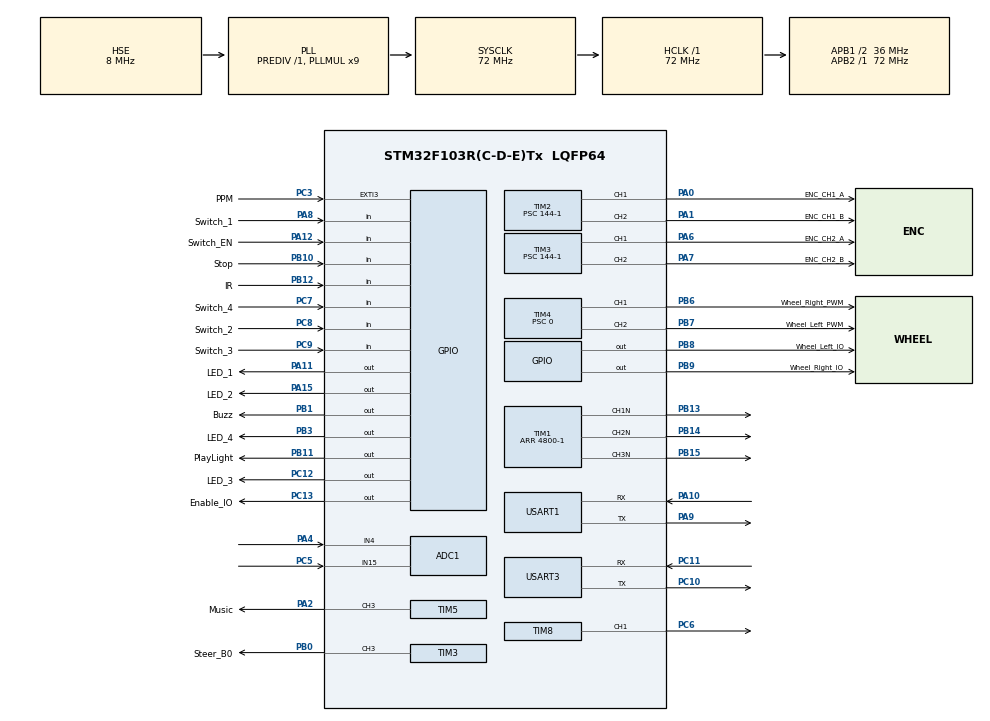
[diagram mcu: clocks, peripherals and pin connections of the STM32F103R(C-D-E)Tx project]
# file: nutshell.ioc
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ADC1.Channel-0\#ChannelRegularConversion=ADC_CHANNEL_4
ADC1.Channel-1\#ChannelRegularConversion=ADC_CHANNEL_15
ADC1.ContinuousConvMode=ENABLE
ADC1.NbrOfConversion=2
ADC1.NbrOfConversionFlag=1
ADC1.Rank-0\#ChannelRegularConversion=1
ADC1.Rank-1\#ChannelRegularConversion=2
ADC1.SamplingTime-0\#ChannelRegularConversion=ADC_SAMPLETIME_239CYCLES_5
ADC1.SamplingTime-1\#ChannelRegularConversion=ADC_SAMPLETIME_239CYCLES_5
ADC1.master=1
Dma.ADC1.0.Direction=DMA_PERIPH_TO_MEMORY
Dma.ADC1.0.Instance=DMA1_Channel1
Dma.ADC1.0.MemDataAlignment=DMA_MDATAALIGN_HALFWORD
Dma.ADC1.0.MemInc=DMA_MINC_ENABLE
Dma.ADC1.0.Mode=DMA_CIRCULAR
Dma.ADC1.0.PeriphDataAlignment=DMA_PDATAALIGN_HALFWORD
Dma.ADC1.0.PeriphInc=DMA_PINC_DISABLE
Dma.ADC1.0.Priority=DMA_PRIORITY_LOW
Dma.Request0=ADC1
Dma.Request1=USART1_TX
Dma.USART1_TX.1.Direction=DMA_MEMORY_TO_PERIPH
Dma.USART1_TX.1.Instance=DMA1_Channel4
Dma.USART1_TX.1.MemDataAlignment=DMA_MDATAALIGN_BYTE
Dma.USART1_TX.1.MemInc=DMA_MINC_ENABLE
Dma.USART1_TX.1.Mode=DMA_NORMAL
Dma.USART1_TX.1.PeriphDataAlignment=DMA_PDATAALIGN_BYTE
Dma.USART1_TX.1.PeriphInc=DMA_PINC_DISABLE
Dma.USART1_TX.1.Priority=DMA_PRIORITY_HIGH
Mcu.Family=STM32F1
Mcu.Name=STM32F103R(C-D-E)Tx
Mcu.Package=LQFP64
Mcu.UserConstants=huart_DBG,$$_USART1_IP_HANDLE_$$;huart_USER,$$_USART3_IP_HANDLE_$$;htim_RC,$$_TIM6_IP_HANDLE_$$
NVIC.DMA1_Channel1_IRQn=true\:0\:0\:false\:false\:true\:false\:true\:true
NVIC.DMA1_Channel4_IRQn=true\:0\:0\:false\:false\:true\:false\:true\:true
NVIC.EXTI3_IRQn=true\:0\:0\:false\:false\:true\:true\:true\:true
NVIC.PriorityGroup=NVIC_PRIORITYGROUP_4
NVIC.TIM6_IRQn=true\:0\:0\:false\:false\:true\:true\:true\:true
NVIC.TIM7_IRQn=true\:15\:0\:false\:false\:true\:false\:true\:true
NVIC.TimeBase=TIM7_IRQn
NVIC.TimeBaseIP=TIM7
PA0-WKUP.GPIO_Label=ENC_CH1_A
PA0-WKUP.GPIO_Speed=GPIO_SPEED_FREQ_HIGH
PA0-WKUP.Signal=S_TIM2_CH1_ETR
PA1.GPIO_Label=ENC_CH1_B
PA1.GPIO_Speed=GPIO_SPEED_FREQ_HIGH
PA1.Signal=S_TIM2_CH2
PA10.Mode=Asynchronous
PA10.Signal=USART1_RX
PA11.GPIO_Label=LED_1
PA11.Signal=GPIO_Output
PA12.GPIO_Label=Switch_EN
PA12.Signal=GPIO_Input
PA13.Mode=Serial_Wire
PA13.Signal=SYS_JTMS-SWDIO
PA14.Mode=Serial_Wire
PA14.Signal=SYS_JTCK-SWCLK
PA15.GPIO_Label=LED_2
PA15.GPIO_Speed=GPIO_SPEED_FREQ_HIGH
PA15.Signal=GPIO_Output
PA2.GPIO_Label=Music
PA2.GPIO_Speed=GPIO_SPEED_FREQ_HIGH
PA2.Signal=S_TIM5_CH3
PA4.Signal=ADCx_IN4
PA6.GPIO_Label=ENC_CH2_A
PA6.GPIO_Speed=GPIO_SPEED_FREQ_HIGH
PA6.Signal=S_TIM3_CH1
PA7.GPIO_Label=ENC_CH2_B
PA7.GPIO_Speed=GPIO_SPEED_FREQ_HIGH
PA7.Signal=S_TIM3_CH2
PA8.GPIO_Label=Switch_1
PA8.GPIO_PuPd=GPIO_PULLUP
PA8.Signal=GPIO_Input
PA9.Mode=Asynchronous
PA9.Signal=USART1_TX
PB0.GPIO_Label=Steer_B0
PB0.GPIO_Speed=GPIO_SPEED_FREQ_HIGH
PB0.Signal=S_TIM3_CH3
PB1.GPIO_Label=Buzz
PB1.Signal=GPIO_Output
PB10.GPIO_Label=Stop
PB10.Signal=GPIO_Input
PB11.GPIO_Label=PlayLight
PB11.Signal=GPIO_Output
PB12.GPIO_Label=IR
PB12.Signal=GPIO_Input
PB13.GPIO_Speed=GPIO_SPEED_FREQ_HIGH
PB13.Mode=Output Compare1 CH1N
PB13.Signal=TIM1_CH1N
PB14.GPIO_Speed=GPIO_SPEED_FREQ_HIGH
PB14.Mode=Output Compare2 CH2N
PB14.Signal=TIM1_CH2N
PB15.GPIO_Speed=GPIO_SPEED_FREQ_HIGH
PB15.Mode=Output Compare3 CH3N
PB15.Signal=TIM1_CH3N
PB3.GPIO_Label=LED_4
PB3.GPIO_Speed=GPIO_SPEED_FREQ_HIGH
PB3.Signal=GPIO_Output
PB6.GPIO_Label=Wheel_Right_PWM
PB6.GPIO_Speed=GPIO_SPEED_FREQ_HIGH
PB6.Signal=S_TIM4_CH1
PB7.GPIO_Label=Wheel_Left_PWM
PB7.Signal=S_TIM4_CH2
PB8.GPIO_Label=Wheel_Left_IO
PB8.GPIO_Speed=GPIO_SPEED_FREQ_HIGH
PB8.Signal=GPIO_Output
PB9.GPIO_Label=Wheel_Right_IO
PB9.GPIO_Speed=GPIO_SPEED_FREQ_HIGH
PB9.Signal=GPIO_Output
PC10.Mode=Asynchronous
PC10.Signal=USART3_TX
PC11.Mode=Asynchronous
PC11.Signal=USART3_RX
PC12.GPIO_Label=LED_3
PC12.GPIO_Speed=GPIO_SPEED_FREQ_HIGH
PC12.Signal=GPIO_Output
PC13-TAMPER-RTC.GPIO_Label=Enable_IO
PC13-TAMPER-RTC.GPIO_Speed=GPIO_SPEED_FREQ_HIGH
PC13-TAMPER-RTC.Signal=GPIO_Output
PC3.GPIO_Label=PPM
PC3.GPIO_ModeDefaultEXTI=GPIO_MODE_IT_FALLING
PC3.Signal=GPXTI3
PC5.Signal=ADCx_IN15
PC6.GPIO_Speed=GPIO_SPEED_FREQ_HIGH
PC6.Signal=S_TIM8_CH1
PC7.GPIO_Label=Switch_4
PC7.GPIO_PuPd=GPIO_PULLUP
PC7.Signal=GPIO_Input
PC8.GPIO_Label=Switch_2
PC8.GPIO_PuPd=GPIO_PULLUP
PC8.Signal=GPIO_Input
PC9.GPIO_Label=Switch_3
PC9.GPIO_PuPd=GPIO_PULLUP
PC9.Signal=GPIO_Input
PD0-OSC_IN.Mode=HSE-External-Oscillator
PD0-OSC_IN.Signal=RCC_OSC_IN
PD1-OSC_OUT.Mode=HSE-External-Oscillator
PD1-OSC_OUT.Signal=RCC_OSC_OUT
ProjectManager.HeapSize=0x200
ProjectManager.StackSize=0x400
ProjectManager.TargetToolchain=CMake
RCC.ADCPresc=RCC_ADCPCLK2_DIV6
RCC.AHBFreq_Value=72000000
RCC.APB1CLKDivider=RCC_HCLK_DIV2
RCC.APB1Freq_Value=36000000
RCC.APB1TimFreq_Value=72000000
RCC.APB2Freq_Value=72000000
RCC.APB2TimFreq_Value=72000000
RCC.HCLKFreq_Value=72000000
RCC.PLLMUL=RCC_PLL_MUL9
RCC.PLLSourceVirtual=RCC_PLLSOURCE_HSE
RCC.RCC_MCOSource=RCC_MCO1SOURCE_PLLCLK
RCC.SYSCLKFreq_VALUE=72000000
RCC.SYSCLKSource=RCC_SYSCLKSOURCE_PLLCLK
RCC.USBFreq_Value=72000000
SH.ADCx_IN15.0=ADC1_IN15,IN15
SH.ADCx_IN4.0=ADC1_IN4,IN4
SH.S_TIM2_CH1_ETR.0=TIM2_CH1,PWM Generation1 CH1
SH.S_TIM2_CH2.0=TIM2_CH2,PWM Generation2 CH2
SH.S_TIM3_CH1.0=TIM3_CH1,PWM Generation1 CH1
SH.S_TIM3_CH2.0=TIM3_CH2,PWM Generation2 CH2
SH.S_TIM3_CH3.0=TIM3_CH3,PWM Generation3 CH3
SH.S_TIM4_CH1.0=TIM4_CH1,PWM Generation1 CH1
SH.S_TIM4_CH2.0=TIM4_CH2,PWM Generation2 CH2
SH.S_TIM5_CH3.0=TIM5_CH3,PWM Generation3 CH3
SH.S_TIM8_CH1.0=TIM8_CH1,PWM Generation1 CH1
TIM1.AutoReloadPreload=TIM_AUTORELOAD_PRELOAD_ENABLE
TIM1.Channel-Output\ Compare1\ CH1N=TIM_CHANNEL_1
TIM1.Channel-Output\ Compare2\ CH2N=TIM_CHANNEL_2
TIM1.Channel-Output\ Compare3\ CH3N=TIM_CHANNEL_3
TIM1.OC1Preload=ENABLE
TIM1.OC2Preload=ENABLE
TIM1.OC3Preload=ENABLE
TIM1.OCMode_1=TIM_OCMODE_TOGGLE
TIM1.OCMode_2=TIM_OCMODE_ACTIVE
TIM1.OCMode_3=TIM_OCMODE_FORCED_ACTIVE
TIM1.OCNPolarity_1=TIM_OCNPOLARITY_HIGH
TIM1.OCNPolarity_2=TIM_OCNPOLARITY_HIGH
TIM1.OCNPolarity_3=TIM_OCNPOLARITY_HIGH
TIM1.Period=4800-1
TIM1.Pulse-Output\ Compare1\ CH1N=500
TIM1.Pulse-Output\ Compare2\ CH2N=500
TIM1.Pulse-Output\ Compare3\ CH3N=500
TIM2.AutoReloadPreload=TIM_AUTORELOAD_PRELOAD_ENABLE
TIM2.Channel-PWM\ Generation1\ CH1=TIM_CHANNEL_1
TIM2.Channel-PWM\ Generation2\ CH2=TIM_CHANNEL_2
TIM2.Period=10000-1
TIM2.Prescaler=144-1
TIM2.Pulse-PWM\ Generation1\ CH1=750
TIM2.Pulse-PWM\ Generation2\ CH2=750
TIM3.AutoReloadPreload=TIM_AUTORELOAD_PRELOAD_ENABLE
TIM3.Channel-PWM\ Generation1\ CH1=TIM_CHANNEL_1
TIM3.Channel-PWM\ Generation2\ CH2=TIM_CHANNEL_2
TIM3.Channel-PWM\ Generation3\ CH3=TIM_CHANNEL_3
TIM3.Period=10000-1
TIM3.Prescaler=144-1
TIM3.Pulse-PWM\ Generation1\ CH1=750
TIM3.Pulse-PWM\ Generation2\ CH2=750
TIM3.Pulse-PWM\ Generation3\ CH3=750
TIM4.AutoReloadPreload=TIM_AUTORELOAD_PRELOAD_ENABLE
TIM4.Channel-PWM\ Generation1\ CH1=TIM_CHANNEL_1
TIM4.Channel-PWM\ Generation2\ CH2=TIM_CHANNEL_2
TIM4.OCFastMode_PWM-PWM\ Generation1\ CH1=TIM_OCFAST_DISABLE
TIM4.Period=4800-1
TIM4.Prescaler=0
TIM4.Pulse-PWM\ Generation1\ CH1=0
TIM5.AutoReloadPreload=TIM_AUTORELOAD_PRELOAD_DISABLE
TIM5.Channel-PWM\ Generation3\ CH3=TIM_CHANNEL_3
TIM5.Period=0
TIM5.Prescaler=72-1
TIM5.Pulse-PWM\ Generation3\ CH3=0
TIM6.AutoReloadPreload=TIM_AUTORELOAD_PRELOAD_ENABLE
TIM6.Period=0xFFFF
TIM6.Prescaler=72-1
TIM8.Channel-PWM\ Generation1\ CH1=TIM_CHANNEL_1
TIM8.Period=4800-1
TIM8.Prescaler=0
USART1.VirtualMode=VM_ASYNC
USART3.VirtualMode=VM_ASYNC
VP_SYS_VS_tim7.Mode=TIM7
VP_TIM1_VS_ClockSourceINT.Mode=Internal
VP_TIM2_VS_ClockSourceINT.Mode=Internal
VP_TIM3_VS_ClockSourceINT.Mode=Internal
VP_TIM4_VS_ClockSourceINT.Mode=Internal
VP_TIM5_VS_ClockSourceINT.Mode=Internal
VP_TIM6_VS_ClockSourceINT.Mode=Enable_Timer
VP_TIM8_VS_ClockSourceINT.Mode=Internal
board=custom

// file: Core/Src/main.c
/* USER CODE BEGIN Header */
// main.c
// The main program
// Date: Oct 2025
/* USER CODE END Header */
#include "main.h"
#include "adc.h"
#include "dma.h"
#include "tim.h"
#include "usart.h"
#include "gpio.h"

/* USER CODE BEGIN Includes */
#include "App.h"

/* USER CODE END Includes */

void SystemClock_Config(void);

int main(void)
{

  /* MCU Configuration--------------------------------------------------------*/

  /* Reset of all peripherals, Initializes the Flash interface and the Systick. */
  HAL_Init();

  /* Configure the system clock */
  SystemClock_Config();

  /* Initialize all configured peripherals */
  MX_GPIO_Init();
  MX_DMA_Init();
  MX_USART1_UART_Init();
  MX_USART3_UART_Init();
  MX_TIM3_Init();
  MX_TIM5_Init();
  MX_TIM4_Init();
  MX_TIM6_Init();
  MX_TIM2_Init();
  MX_TIM8_Init();
  MX_TIM1_Init();
  MX_ADC1_Init();
  /* USER CODE BEGIN 2 */
  App();

  /* USER CODE END 2 */

  /* Infinite loop */
  while (1)
  {

  }
}

void SystemClock_Config(void)
{
  RCC_OscInitTypeDef RCC_OscInitStruct = {0};
  RCC_ClkInitTypeDef RCC_ClkInitStruct = {0};
  RCC_PeriphCLKInitTypeDef PeriphClkInit = {0};

  /** Initializes the RCC Oscillators according to the specified parameters
  * in the RCC_OscInitTypeDef structure.
  */
  RCC_OscInitStruct.OscillatorType = RCC_OSCILLATORTYPE_HSE;
  RCC_OscInitStruct.HSEState = RCC_HSE_ON;
  RCC_OscInitStruct.HSEPredivValue = RCC_HSE_PREDIV_DIV1;
  RCC_OscInitStruct.HSIState = RCC_HSI_ON;
  RCC_OscInitStruct.PLL.PLLState = RCC_PLL_ON;
  RCC_OscInitStruct.PLL.PLLSource = RCC_PLLSOURCE_HSE;
  RCC_OscInitStruct.PLL.PLLMUL = RCC_PLL_MUL9;
  if (HAL_RCC_OscConfig(&RCC_OscInitStruct) != HAL_OK)
  {
    Error_Handler();
  }

  /** Initializes the CPU, AHB and APB buses clocks
  */
  RCC_ClkInitStruct.ClockType = RCC_CLOCKTYPE_HCLK|RCC_CLOCKTYPE_SYSCLK
                              |RCC_CLOCKTYPE_PCLK1|RCC_CLOCKTYPE_PCLK2;
  RCC_ClkInitStruct.SYSCLKSource = RCC_SYSCLKSOURCE_PLLCLK;
  RCC_ClkInitStruct.AHBCLKDivider = RCC_SYSCLK_DIV1;
  RCC_ClkInitStruct.APB1CLKDivider = RCC_HCLK_DIV2;
  RCC_ClkInitStruct.APB2CLKDivider = RCC_HCLK_DIV1;

  if (HAL_RCC_ClockConfig(&RCC_ClkInitStruct, FLASH_LATENCY_2) != HAL_OK)
  {
    Error_Handler();
  }
  PeriphClkInit.PeriphClockSelection = RCC_PERIPHCLK_ADC;
  PeriphClkInit.AdcClockSelection = RCC_ADCPCLK2_DIV6;
  if (HAL_RCCEx_PeriphCLKConfig(&PeriphClkInit) != HAL_OK)
  {
    Error_Handler();
  }
}

void HAL_TIM_PeriodElapsedCallback(TIM_HandleTypeDef *htim)
{
  if (htim->Instance == TIM7)
  {
    HAL_IncTick();
  }
}

void Error_Handler(void)
{
  __disable_irq();
  while (1)
  {
  }
}
